# 3061MNPIK8 register map
File version: 1.0
Registers are 32-bit, access per field, reset 0x0 unless marked. A register's access mark holds for its fields unless they carry their own. Offsets are from the block's base; [hi:lo] are bit positions; {n}, {i} and the like mark numbered series.

## CAPM0 — CAPM peripheral interface
Base 0x14B00000
Same registers: CAPM1 0x14B01000, CAPM2 0x14B02000
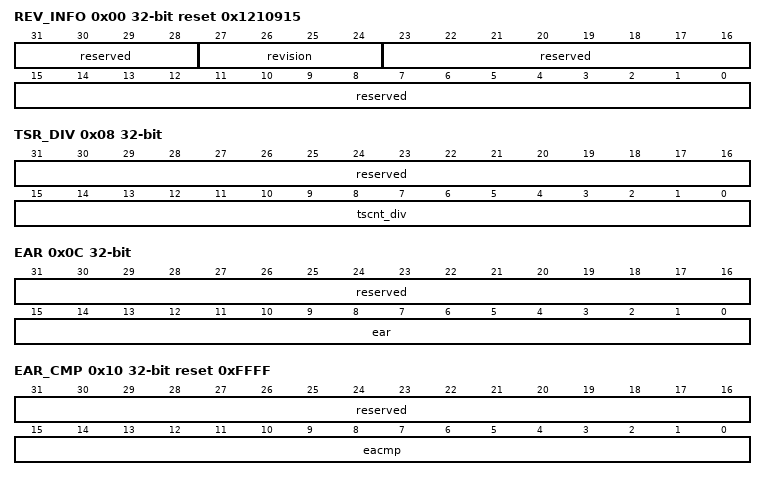
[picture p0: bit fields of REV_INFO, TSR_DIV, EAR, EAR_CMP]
0x00 REV_INFO ro reset 0x1210915 — Revision Information，版本信息寄存器。
  [31:28] reserved — 保留。
  [27:24] revision — IP版本号。
  [23:0] reserved — 保留。
0x04 TSR ro — Time-Stamp Register，时间戳计数器。
  [31:0] tsr — 时间戳计数器，可用于监视计数器状态。
0x08 TSR_DIV — Time-Stamp Divider Register，时间戳计数器分频配置寄存器。
  [31:16] reserved ro — 保留。
  [15:0] tscnt_div rw — 计数器分频。 0x0000：每1clk计数器+1； 0x0001：每2clk计数器+1； 0x0002：每3clk计数器+1； … 0xFFFF：每65536clk计数器+1。
0x0C EAR ro — Edge Amount Register，边沿数量寄存器。
  [31:16] reserved — 保留。
  [15:0] ear — 边沿数量计数值，只读。
0x10 EAR_CMP reset 0xFFFF — EAR Compare Value Register，边沿数量比较寄存器。
  [31:16] reserved ro — 保留。
  [15:0] eacmp rw — 边沿数量计数值，只读。
0x14 SYNC_PHS rw — Sync Phase，同步相位寄存器。
  [31:0] sync_phs — 计数器同步相位值寄存器，硬件同步源或软件同步（sync_sw）有效时，将TSR寄存器置位为该值。
{0x18+4i} ECR{i} ro (i=0..2) — Event {i} Capture Register，事件{i}时间戳寄存器。
  [31:0] ecr{i} — 捕获寄存器{i}（事件{i}）。
0x24 ECR3 ro — Event 3 Capture Register，事件3时间戳寄存器。
  [31:0] ecr3 — 捕获寄存器3（事件3）
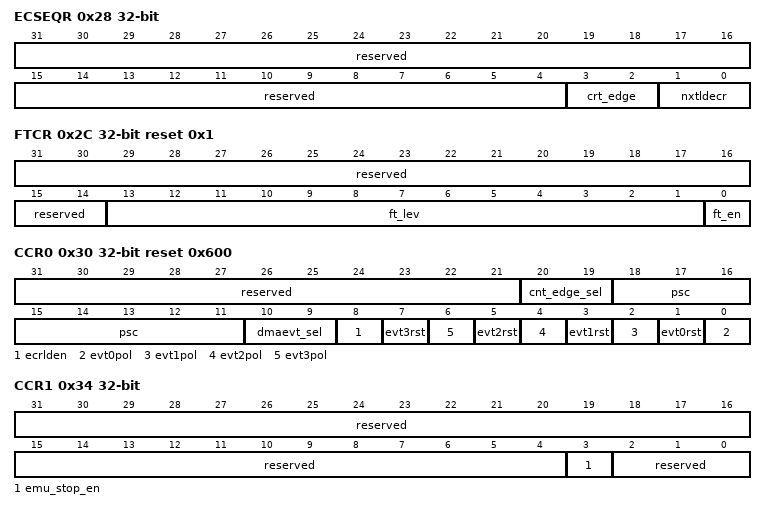
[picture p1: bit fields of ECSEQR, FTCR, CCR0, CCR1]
0x28 ECSEQR ro — Event Capture Sequence Register，事件捕获序列寄存器。
  [31:4] reserved — 保留。
  [3:2] crt_edge — 当前输入信号电平（反映原输入信号的电平，不受预分频影响）。 00：当前为低电平。 01：上升沿； 10：下降沿； 11：高电平。
  [1:0] nxtldecr — 读取下个被加载的ECR。 00：ECR0； 01：ECR1； 10：ECR2； 11：ECR3。
0x2C FTCR reset 0x1 — Filter Control Register，滤波控制寄存器。
  [31:14] reserved ro — 保留。
  [13:1] ft_lev rw — 滤波等级配置。 0x0000：不过滤毛刺； 0x0001：过滤最宽1时钟周期宽度毛刺； ... 0x1FFF：过滤最宽8191时钟周期宽度毛刺。
  [0] ft_en rw — 滤波功能使能开关。 0：关闭； 1：开启。
0x30 CCR0 reset 0x600 — Control & Configure Register 0，输入信号处理，事件产生和行为模式寄存器。
  [31:21] reserved ro — 保留。
  [20:19] cnt_edge_sel rw — 边沿数量计数的边沿类型选择。 00：不记录边沿数量； 01：对上升沿数量计数； 10：对下降沿数量计数； 11：对双沿数量计数。
  [18:11] psc rw — 输入信号预分频系数。 0x00：不分频； 0x01：输入信号2倍分频； 0x02：输入信号4倍分频； ... 0xFF：输入信号510倍分频。
  [10:9] dmaevt_sel rw — 在捕获序列中，决定由哪个事件产生DMA请求。 00：事件0（EVT0）； 01：事件1（EVT1）； 10：事件2（EVT2）； 11：事件3（EVT3）。
  [8] ecrlden rw — 捕获使能。 0：关闭捕获； 1：开启捕获。
  [2n+1] evt{n}rst rw (n=0..3) — 事件{n}（EVT{n}）是否复位TSR。 0：EVT{n}不复位TSR； 1：EVT{n}复位TSR。
  [2n] evt{n}pol rw (n=0..3) — 事件{n}（EVT{n}）捕获边沿选择。 0：EVT{n}捕获下降沿； 1：EVT{n}捕获上升沿。
0x34 CCR1 — Control & Configure Register 1，仿真器模式寄存器。
  [31:4] reserved ro — 保留。
  [3] emu_stop_en rw — 仿真器停止TSR使能。 0：禁止仿真器停止计数器； 1：允许仿真器停止计数器。
  [2:0] reserved ro — 保留。
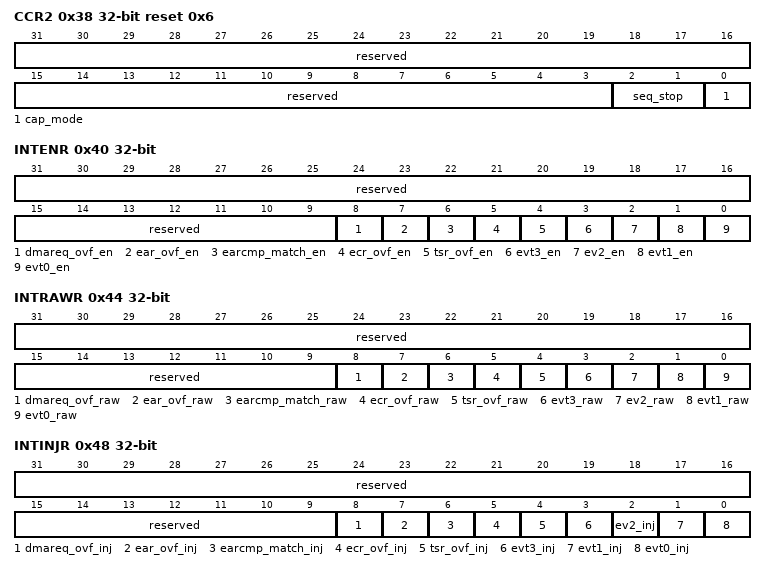
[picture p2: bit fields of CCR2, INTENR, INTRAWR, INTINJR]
0x38 CCR2 reset 0x6 — Control & Configure Register 2，工作模式寄存器。
  [31:3] reserved ro — 保留。
  [2:1] seq_stop rw — 捕获序列终点/循环边界。 00：事件0（EVT0）为捕获终点/循环边界； 01：事件1（EVT1）为捕获终点/循环边界； 10：事件2（EVT2）为捕获终点/循环边界； 11：事件3（EVT3）为捕获终点/循环边界。
  [0] cap_mode rw — 捕获模式选择。 0：循环捕获模式；（到循环边界后循环） 1：单轮次捕获模式。（到捕获终点后结束）
0x40 INTENR — Interrupt Enable Register，中断使能寄存器。
  [31:9] reserved ro — 保留。
  [8] dmareq_ovf_en rw — DMA请求溢出中断使能。不使能时，即屏蔽相应的中断状态，不影响相应的原始中断。若全部不使能，模块不会上报中断给CPU。 0：不使能； 1：使能。
  [7] ear_ovf_en rw — 边沿数量计数溢出中断使能。 0：不使能； 1：使能。
  [6] earcmp_match_en rw — 边沿数量计数比较匹配中断使能。 0：不使能； 1：使能。
  [5] ecr_ovf_en rw — 捕获溢出中断使能。 0：不使能； 1：使能。
  [4] tsr_ovf_en rw — TSR溢出中断使能。 0：不使能； 1：使能。
  [3] evt3_en rw — 事件3中断使能。 0：不使能； 1：使能。
  [2] ev2_en rw — 事件2中断使能。 0：不使能； 1：使能。
  [1] evt1_en rw — 事件1中断使能。 0：不使能； 1：使能。
  [0] evt0_en rw — 事件0中断使能。 0：不使能； 1：使能。
0x44 INTRAWR — Raw Interrupt Register，原始中断寄存器。
  [31:9] reserved ro — 保留。
  [8] dmareq_ovf_raw rw write-1-clears — DMA请求溢出原始中断，写1清除。 0：无原始中断； 1：有原始中断。
  [7] ear_ovf_raw rw write-1-clears — 边沿数量计数溢出原始中断，写1清除。 0：无原始中断； 1：有原始中断。
  [6] earcmp_match_raw rw write-1-clears — 边沿数量比较匹配原始中断，写1清除。 0：无原始中断； 1：有原始中断。
  [5] ecr_ovf_raw rw write-1-clears — 捕获溢出原始中断，写1清除。 0：无原始中断； 1：有原始中断。
  [4] tsr_ovf_raw rw write-1-clears — TSR溢出原始中断，写1清除。 0：无原始中断； 1：有原始中断。
  [3] evt3_raw rw write-1-clears — 事件3原始中断，写1清除。 0：无原始中断； 1：有原始中断。
  [2] ev2_raw rw write-1-clears — 事件2原始中断，写1清除。 0：无原始中断； 1：有原始中断。
  [1] evt1_raw rw write-1-clears — 事件1原始中断，写1清除。 0：无原始中断； 1：有原始中断。
  [0] evt0_raw rw write-1-clears — 事件0原始中断，写1清除。 0：无原始中断； 1：有原始中断。
0x48 INTINJR — Interrupt Injection Register，中断注入寄存器。
  [31:9] reserved ro — 保留。
  [8] dmareq_ovf_inj rw write-1-clears — 注入DMA请求溢出原始中断。写1自动清零。 0：不注入； 1：注入。
  [7] ear_ovf_inj rw write-1-clears — 注入边沿数量计数溢出原始中断。写1自动清零。 0：不注入； 1：注入。
  [6] earcmp_match_inj rw write-1-clears — 注入边沿数量比较匹配原始中断。写1自动清零。 0：不注入； 1：注入。
  [5] ecr_ovf_inj rw write-1-clears — 注入捕获溢出原始中断。写1自动清零。 0：不注入； 1：注入。
  [4] tsr_ovf_inj rw write-1-clears — 注入TSR溢出原始中断。写1自动清零。 0：不注入； 1：注入。
  [3] evt3_inj rw write-1-clears — 注入事件3原始中断。写1自动清零。 0：不注入； 1：注入。
  [2] ev2_inj rw write-1-clears — 注入事件2原始中断。写1自动清零。 0：不注入； 1：注入。
  [1] evt1_inj rw write-1-clears — 注入事件1原始中断。写1自动清零。 0：不注入； 1：注入。
  [0] evt0_inj rw write-1-clears — 注入事件0原始中断。写1自动清零。 0：不注入； 1：注入。
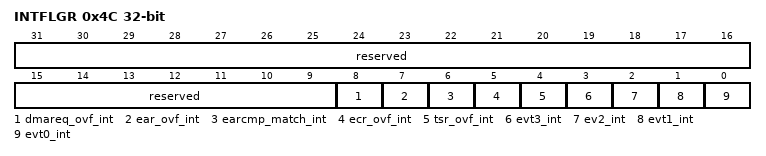
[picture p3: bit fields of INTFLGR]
0x4C INTFLGR ro — Interrupt Flag Register，中断标志/状态寄存器。
  [31:9] reserved — 保留。
  [8] dmareq_ovf_int — DMA请求溢出中断标志。 0：无中断； 1：有中断。
  [7] ear_ovf_int — 边沿数量计数溢出中断标志。 0：无中断； 1：有中断。
  [6] earcmp_match_int — 边沿数量计数比较匹配中断标志。 0：无中断； 1：有中断。
  [5] ecr_ovf_int — 捕获溢出中断标志。 0：无中断； 1：有中断。
  [4] tsr_ovf_int — TSR溢出中断标志。 0：无中断； 1：有中断。
  [3] evt3_int — 事件3中断标志。 0：无中断； 1：有中断。
  [2] ev2_int — 事件2中断标志。 0：无中断； 1：有中断。
  [1] evt1_int — 事件1中断标志。 0：无中断； 1：有中断。
  [0] evt0_int — 事件0中断标志。 0：无中断； 1：有中断。
